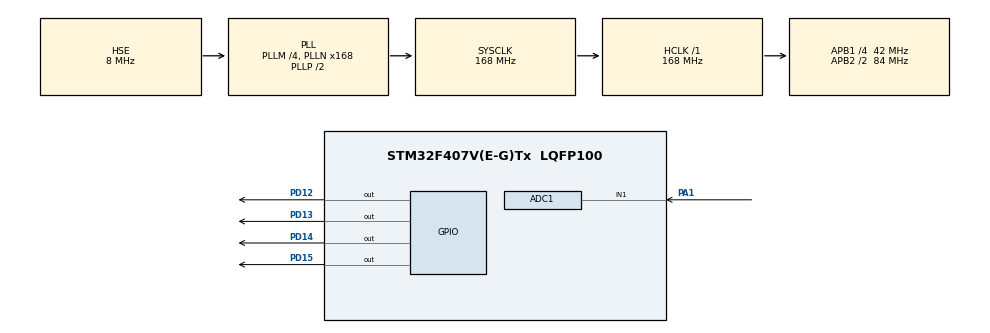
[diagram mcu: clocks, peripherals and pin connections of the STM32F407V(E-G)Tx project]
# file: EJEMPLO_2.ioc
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ADC1.Channel-0\#ChannelRegularConversion=ADC_CHANNEL_1
ADC1.DMAContinuousRequests=ENABLE
ADC1.ExternalTrigConv=ADC_EXTERNALTRIGCONV_T2_TRGO
ADC1.ExternalTrigConvEdge=ADC_EXTERNALTRIGCONVEDGE_FALLING
ADC1.NbrOfConversionFlag=1
ADC1.Rank-0\#ChannelRegularConversion=1
ADC1.SamplingTime-0\#ChannelRegularConversion=ADC_SAMPLETIME_3CYCLES
ADC1.master=1
Dma.ADC1.0.Direction=DMA_PERIPH_TO_MEMORY
Dma.ADC1.0.FIFOMode=DMA_FIFOMODE_DISABLE
Dma.ADC1.0.Instance=DMA2_Stream0
Dma.ADC1.0.MemDataAlignment=DMA_MDATAALIGN_HALFWORD
Dma.ADC1.0.MemInc=DMA_MINC_ENABLE
Dma.ADC1.0.Mode=DMA_CIRCULAR
Dma.ADC1.0.PeriphDataAlignment=DMA_PDATAALIGN_HALFWORD
Dma.ADC1.0.PeriphInc=DMA_PINC_DISABLE
Dma.ADC1.0.Priority=DMA_PRIORITY_LOW
Dma.Request0=ADC1
Mcu.Family=STM32F4
Mcu.Name=STM32F407V(E-G)Tx
Mcu.Package=LQFP100
NVIC.DMA2_Stream0_IRQn=true\:0\:0\:false\:false\:true\:false\:true
NVIC.PriorityGroup=NVIC_PRIORITYGROUP_4
PA1.Signal=ADCx_IN1
PA13.Mode=Serial_Wire
PA13.Signal=SYS_JTMS-SWDIO
PA14.Mode=Serial_Wire
PA14.Signal=SYS_JTCK-SWCLK
PD12.Signal=GPIO_Output
PD13.Signal=GPIO_Output
PD14.Signal=GPIO_Output
PD15.Signal=GPIO_Output
PH0-OSC_IN.Mode=HSE-External-Oscillator
PH0-OSC_IN.Signal=RCC_OSC_IN
PH1-OSC_OUT.Mode=HSE-External-Oscillator
PH1-OSC_OUT.Signal=RCC_OSC_OUT
ProjectManager.HeapSize=0x200
ProjectManager.StackSize=0x400
ProjectManager.TargetToolchain=MDK-ARM V5.27
RCC.48MHZClocksFreq_Value=84000000
RCC.AHBFreq_Value=168000000
RCC.APB1CLKDivider=RCC_HCLK_DIV4
RCC.APB1Freq_Value=42000000
RCC.APB1TimFreq_Value=84000000
RCC.APB2CLKDivider=RCC_HCLK_DIV2
RCC.APB2Freq_Value=84000000
RCC.APB2TimFreq_Value=168000000
RCC.CortexFreq_Value=168000000
RCC.HCLKFreq_Value=168000000
RCC.HSE_VALUE=8000000
RCC.HSI_VALUE=16000000
RCC.LSE_VALUE=32768
RCC.PLLM=4
RCC.PLLN=168
RCC.PLLSourceVirtual=RCC_PLLSOURCE_HSE
RCC.SYSCLKFreq_VALUE=168000000
RCC.SYSCLKSource=RCC_SYSCLKSOURCE_PLLCLK
RCC.VCOOutputFreq_Value=336000000
SH.ADCx_IN1.0=ADC1_IN1,IN1
TIM2.Period=100000-1
TIM2.Prescaler=84-1
TIM2.TIM_MasterOutputTrigger=TIM_TRGO_UPDATE
TIM2.TIM_MasterSlaveMode=TIM_MASTERSLAVEMODE_ENABLE
VP_TIM2_VS_ClockSourceINT.Mode=Internal
board=custom

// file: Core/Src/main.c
/* USER CODE BEGIN Header */
/**
  ******************************************************************************
  * @file           : main.c
  * @brief          : Main program body
  ******************************************************************************
  * @attention
  *
  * <h2><center>&copy; Copyright (c) 2020 STMicroelectronics.
  * All rights reserved.</center></h2>
  *
  * This software component is licensed by ST under BSD 3-Clause license,
  * the "License"; You may not use this file except in compliance with the
  * License. You may obtain a copy of the License at:
  *                        opensource.org/licenses/BSD-3-Clause
  *
  ******************************************************************************
  */
/* USER CODE END Header */
#include "main.h"
#include "adc.h"
#include "dma.h"
#include "tim.h"
#include "gpio.h"

/* USER CODE BEGIN Includes */
#include "arm_math.h"
/* USER CODE END Includes */

/* USER CODE BEGIN PM */
#define ADC_BUF_SIZE	1
/* USER CODE END PM */

/* USER CODE BEGIN PV */
uint16_t ADC_buffer;
volatile uint16_t data;
/* USER CODE END PV */

void SystemClock_Config(void);

int main(void)
{

  /* MCU Configuration--------------------------------------------------------*/

  /* Reset of all peripherals, Initializes the Flash interface and the Systick. */
  HAL_Init();

  /* Configure the system clock */
  SystemClock_Config();

  /* Initialize all configured peripherals */
  MX_GPIO_Init();
  MX_DMA_Init();
  MX_ADC1_Init();
  MX_TIM2_Init();
  /* USER CODE BEGIN 2 */
	if(HAL_ADC_Start_DMA(&hadc1,(uint32_t* ) &ADC_buffer, ADC_BUF_SIZE) != HAL_OK){
	  Error_Handler();
  }
  if(HAL_TIM_Base_Start(&htim2)!= HAL_OK){
	  Error_Handler();
  }
  /* USER CODE END 2 */

  /* Infinite loop */
  while (1)
  {

    /* USER CODE BEGIN 3 */
		HAL_GPIO_TogglePin(GPIOD,GPIO_PIN_13 | GPIO_PIN_14 | GPIO_PIN_15);
		HAL_Delay(100);
  }
  /* USER CODE END 3 */
}

void SystemClock_Config(void)
{
  RCC_OscInitTypeDef RCC_OscInitStruct = {0};
  RCC_ClkInitTypeDef RCC_ClkInitStruct = {0};

  /** Configure the main internal regulator output voltage
  */
  __HAL_RCC_PWR_CLK_ENABLE();
  __HAL_PWR_VOLTAGESCALING_CONFIG(PWR_REGULATOR_VOLTAGE_SCALE1);
  /** Initializes the RCC Oscillators according to the specified parameters
  * in the RCC_OscInitTypeDef structure.
  */
  RCC_OscInitStruct.OscillatorType = RCC_OSCILLATORTYPE_HSE;
  RCC_OscInitStruct.HSEState = RCC_HSE_ON;
  RCC_OscInitStruct.PLL.PLLState = RCC_PLL_ON;
  RCC_OscInitStruct.PLL.PLLSource = RCC_PLLSOURCE_HSE;
  RCC_OscInitStruct.PLL.PLLM = 4;
  RCC_OscInitStruct.PLL.PLLN = 168;
  RCC_OscInitStruct.PLL.PLLP = RCC_PLLP_DIV2;
  RCC_OscInitStruct.PLL.PLLQ = 4;
  if (HAL_RCC_OscConfig(&RCC_OscInitStruct) != HAL_OK)
  {
    Error_Handler();
  }
  /** Initializes the CPU, AHB and APB buses clocks
  */
  RCC_ClkInitStruct.ClockType = RCC_CLOCKTYPE_HCLK|RCC_CLOCKTYPE_SYSCLK
                              |RCC_CLOCKTYPE_PCLK1|RCC_CLOCKTYPE_PCLK2;
  RCC_ClkInitStruct.SYSCLKSource = RCC_SYSCLKSOURCE_PLLCLK;
  RCC_ClkInitStruct.AHBCLKDivider = RCC_SYSCLK_DIV1;
  RCC_ClkInitStruct.APB1CLKDivider = RCC_HCLK_DIV4;
  RCC_ClkInitStruct.APB2CLKDivider = RCC_HCLK_DIV2;

  if (HAL_RCC_ClockConfig(&RCC_ClkInitStruct, FLASH_LATENCY_5) != HAL_OK)
  {
    Error_Handler();
  }
}

/* USER CODE BEGIN 4 */
void HAL_ADC_ConvCpltCallback(ADC_HandleTypeDef* hadc)
{
	HAL_GPIO_TogglePin(GPIOD, GPIO_PIN_12 );
	data = ADC_buffer;
}
/* USER CODE END 4 */

void Error_Handler(void)
{
}

/************************ (C) COPYRIGHT STMicroelectronics *****END OF FILE****/
